AUTOSAR XML (schema 4-0-2)
package /TestBswM
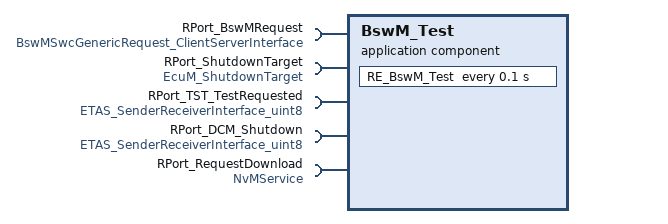
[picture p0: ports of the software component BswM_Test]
  application sw component type BswM_Test
    5 x require port:
      RPort_BswMRequest: required-interface=BswMSwcGenericRequest_ClientServerInterface
      RPort_ShutdownTarget: required-interface=EcuM_ShutdownTarget
      RPort_TST_TestRequested: required-interface=ETAS_SenderReceiverInterface_uint8
      RPort_DCM_Shutdown: required-interface=ETAS_SenderReceiverInterface_uint8
      RPort_RequestDownload: required-interface=NvMService
    behavior TestBswM_IB: data-type-mapping=WdgM_Type_Map
      timing event TimingEvent_BswM: start-on-event=RE_BswM_Test, period=0.1
      runnable RE_BswM_Test: symbol=RE_BswM_Test_func
        data-receive-point-by-values:
          access DRPV_uint8_0: accessed-variable=RPort_TST_TestRequested.uint8
          access DRPV_uint8_1: accessed-variable=RPort_DCM_Shutdown.uint8
        sync call SynchronousServerCallPoint_0: operation=RPort_BswMRequest.BswMSwcGenericRequest
        sync call SynchronousServerCallPoint_1: operation=RPort_ShutdownTarget.SelectShutdownTarget
        sync call SynchronousServerCallPoint_2: operation=RPort_RequestDownload.SetRamBlockStatus
